# STM32H725 register map
File version: 2.1
CPU: CM7 r0p1, little endian, MPU, FPU, 4 interrupt priority bits
Registers are 32-bit, read-write, reset 0x0 unless marked. A register's access mark holds for its fields unless they carry their own. Offsets are from the block's base; [hi:lo] are bit positions; {n}, {i} and the like mark numbered series.

## CRC — Cryptographic processor
Base 0x58024C00
0x00 DR reset 0xFFFFFFFF — Data register
  [31:0] DR — Data Register
0x04 IDR — Independent Data register
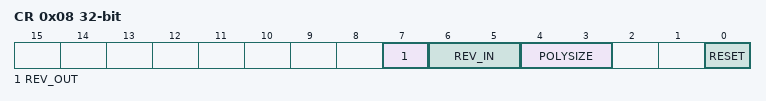
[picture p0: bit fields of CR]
0x08 CR access per field — Control register
  [7] REV_OUT rw — Reverse output data
  [6:5] REV_IN rw — Reverse input data
  [4:3] POLYSIZE rw — Polynomial size
  [0] RESET wo — RESET bit
0x10 INIT — Initial CRC value
  [31:0] CRC_INIT — Programmable initial CRC value
0x14 POL reset 0x4C11DB7 — CRC polynomial
  [31:0] POL — Programmable polynomial

## DCMI — Digital camera interface
Base 0x48020000
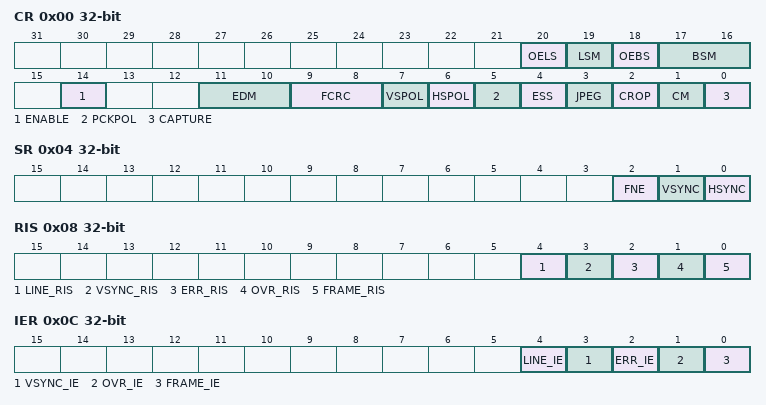
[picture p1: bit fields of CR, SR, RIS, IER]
0x00 CR — control register 1
  [20] OELS — Odd/Even Line Select (Line Select Start)
  [19] LSM — Line Select mode
  [18] OEBS — Odd/Even Byte Select (Byte Select Start)
  [17:16] BSM — Byte Select mode
  [14] ENABLE — DCMI enable
  [11:10] EDM — Extended data mode
  [9:8] FCRC — Frame capture rate control
  [7] VSPOL — Vertical synchronization polarity
  [6] HSPOL — Horizontal synchronization polarity
  [5] PCKPOL — Pixel clock polarity
  [4] ESS — Embedded synchronization select
  [3] JPEG — JPEG format
  [2] CROP — Crop feature
  [1] CM — Capture mode
  [0] CAPTURE — Capture enable
0x04 SR ro — status register
  [2] FNE — FIFO not empty
  [1] VSYNC
  [0] HSYNC
0x08 RIS ro — raw interrupt status register
  [4] LINE_RIS — Line raw interrupt status
  [3] VSYNC_RIS — VSYNC raw interrupt status
  [2] ERR_RIS — Synchronization error raw interrupt status
  [1] OVR_RIS — Overrun raw interrupt status
  [0] FRAME_RIS — Capture complete raw interrupt status
0x0C IER — interrupt enable register
  [4] LINE_IE — Line interrupt enable
  [3] VSYNC_IE — VSYNC interrupt enable
  [2] ERR_IE — Synchronization error interrupt enable
  [1] OVR_IE — Overrun interrupt enable
  [0] FRAME_IE — Capture complete interrupt enable
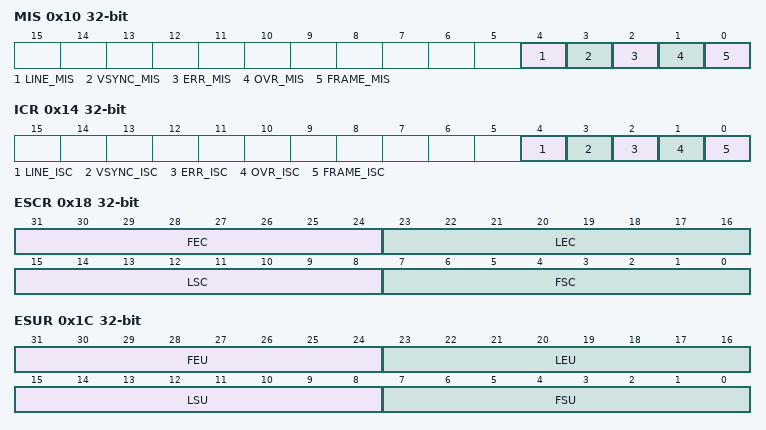
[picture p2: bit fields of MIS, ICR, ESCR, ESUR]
0x10 MIS ro — masked interrupt status register
  [4] LINE_MIS — Line masked interrupt status
  [3] VSYNC_MIS — VSYNC masked interrupt status
  [2] ERR_MIS — Synchronization error masked interrupt status
  [1] OVR_MIS — Overrun masked interrupt status
  [0] FRAME_MIS — Capture complete masked interrupt status
0x14 ICR wo — interrupt clear register
  [4] LINE_ISC — line interrupt status clear
  [3] VSYNC_ISC — Vertical synch interrupt status clear
  [2] ERR_ISC — Synchronization error interrupt status clear
  [1] OVR_ISC — Overrun interrupt status clear
  [0] FRAME_ISC — Capture complete interrupt status clear
0x18 ESCR — embedded synchronization code register
  [31:24] FEC — Frame end delimiter code
  [23:16] LEC — Line end delimiter code
  [15:8] LSC — Line start delimiter code
  [7:0] FSC — Frame start delimiter code
0x1C ESUR — embedded synchronization unmask register
  [31:24] FEU — Frame end delimiter unmask
  [23:16] LEU — Line end delimiter unmask
  [15:8] LSU — Line start delimiter unmask
  [7:0] FSU — Frame start delimiter unmask
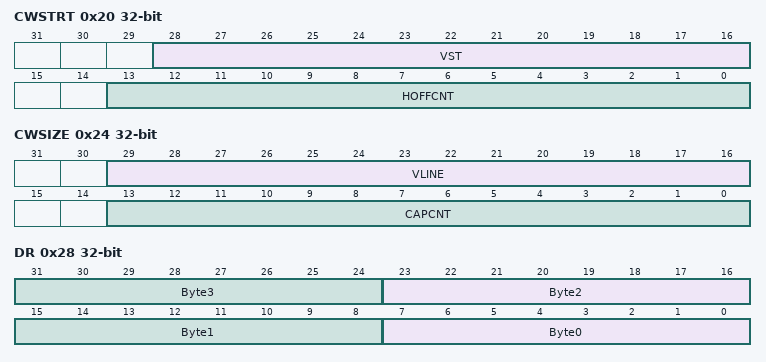
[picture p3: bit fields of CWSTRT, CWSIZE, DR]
0x20 CWSTRT — crop window start
  [28:16] VST — Vertical start line count
  [13:0] HOFFCNT — Horizontal offset count
0x24 CWSIZE — crop window size
  [29:16] VLINE — Vertical line count
  [13:0] CAPCNT — Capture count
0x28 DR ro — data register
  [8n+7:8n] Byte{n} (n=0..3) — Data byte {n}

## DELAY_Block_SDMMC1
Base 0x52008000
Same registers: DELAY_Block_SDMMC2 0x48022800, Delay_Block_OCTOSPI1 0x52006000, Delay_Block_OCTOSPI2 0x5200B000
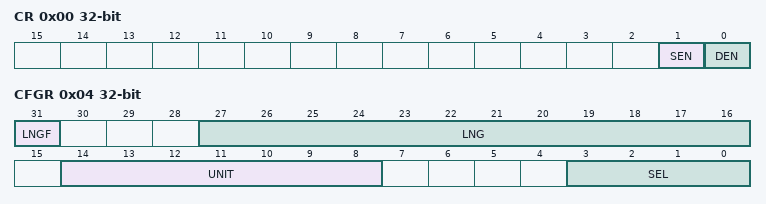
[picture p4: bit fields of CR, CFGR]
0x00 CR — DLYB control register
  [1] SEN — Sampler length enable bit
  [0] DEN — Delay block enable bit
0x04 CFGR — DLYB configuration register
  [31] LNGF — Length valid flag
  [27:16] LNG — Delay line length value
  [14:8] UNIT — Delay Defines the delay of a Unit delay cell
  [3:0] SEL — Select the phase for the Output clock

## DMAMUX1 — DMAMUX
Base 0x40020800
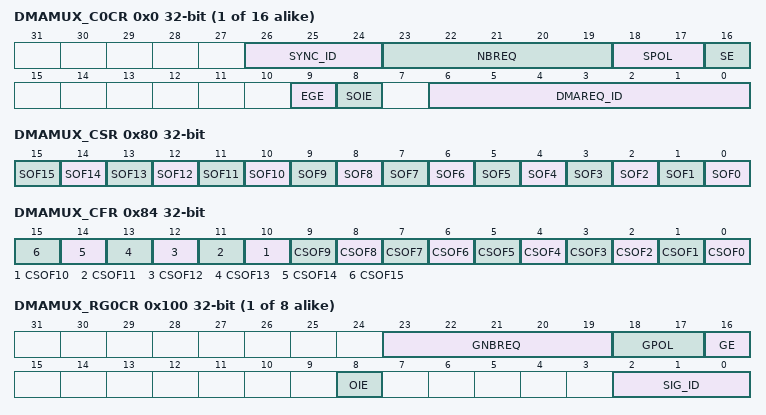
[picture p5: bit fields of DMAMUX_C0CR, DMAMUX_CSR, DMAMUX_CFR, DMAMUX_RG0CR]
{0x0+4i} DMAMUX_C{i}CR (i=0..15)
  [26:24] SYNC_ID — Synchronization identification Selects the synchronization input (see inputs to resources).
  [23:19] NBREQ — Number of DMA requests minus 1 to forward Defines the number of DMA requests to forward to the DMA controller after a synchronization event, and/or the number of DMA requests before an output event is generated. This field shall only be written when both SE and EGE bits are low.
  [18:17] SPOL — Synchronization polarity Defines the edge polarity of the selected synchronization input:
    0=No event, i.e. no synchronization nor detection.; 1=Rising edge; 2=Falling edge; 3=Rising and falling edges
  [16] SE — Synchronization enable
    0=Synchronization disabled; 1=Synchronization enabled
  [9] EGE — Event generation enable
    0=Event generation disabled; 1=Event generation enabled
  [8] SOIE — Synchronization overrun interrupt enable
    0=Interrupt disabled; 1=Interrupt enabled
  [6:0] DMAREQ_ID — DMA request identification Selects the input DMA request. See the DMAMUX table about assignments of multiplexer inputs to resources.
0x80 DMAMUX_CSR ro
  [n] SOF{n} (n=0..15) — Synchronization overrun event flag The flag is set when a synchronization event occurs on a DMA request line multiplexer channel x, while the DMA request counter value is lower than NBREQ. The flag is cleared by writing 1 to the corresponding CSOFx bit in DMAMUX_CFR register. For DMAMUX2 bits 15:8 are reserved, keep them at reset value.
0x84 DMAMUX_CFR wo
  [n] CSOF{n} (n=0..15) — Clear synchronization overrun event flag Writing 1 in each bit clears the corresponding overrun flag SOFx in the DMAMUX_CSR register.
{0x100+4i} DMAMUX_RG{i}CR (i=0..7)
  [23:19] GNBREQ — Number of DMA requests to be generated (minus 1) Defines the number of DMA requests to be generated after a trigger event. The actual number of generated DMA requests is GNBREQ +1. Note: This field must be written only when GE bit is disabled.
  [18:17] GPOL — DMA request generator trigger polarity Defines the edge polarity of the selected trigger input
    0=No event, i.e. no trigger detection nor generation.; 1=Rising edge; 2=Falling edge; 3=Rising and falling edges
  [16] GE — DMA request generator channel x enable
    0=DMA request generator channel x disabled; 1=DMA request generator channel x enabled
  [8] OIE — Trigger overrun interrupt enable
    0=Interrupt on a trigger overrun event occurrence is disabled; 1=Interrupt on a trigger overrun event occurrence is enabled
  [2:0] SIG_ID — Signal identification Selects the DMA request trigger input used for the channel x of the DMA request generator
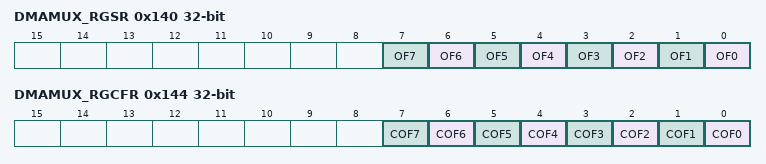
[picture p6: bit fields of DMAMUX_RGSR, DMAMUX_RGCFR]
0x140 DMAMUX_RGSR ro
  [n] OF{n} (n=0..7) — [:0]: Trigger overrun event flag The flag is set when a new trigger event occurs on DMA request generator channel x, before the request counter underrun (the internal request counter programmed via the GNBREQ field of the DMAMUX_RGxCR register). The flag is cleared by writing 1 to the corresponding COFx bit in the DMAMUX_RGCFR register.
0x144 DMAMUX_RGCFR wo
  [n] COF{n} (n=0..7) — Clear trigger overrun event flag Writing 1 in each bit clears the corresponding overrun flag OFx in the DMAMUX_RGSR register.

## Notices in the file
Copyright (c) 2025 STMicroelectronics.
SPDX-License-Identifier: Apache-2.0
Licensed under the Apache License, Version 2.0 (the "License");
you may not use this file except in compliance with the License.
You may obtain a copy of the License at
http://www.apache.org/licenses/LICENSE-2.0
Unless required by applicable law or agreed to in writing, software
distributed under the License is distributed on an "AS IS" BASIS,
WITHOUT WARRANTIES OR CONDITIONS OF ANY KIND, either express or implied.
See the License for the specific language governing permissions and
limitations under the License.
